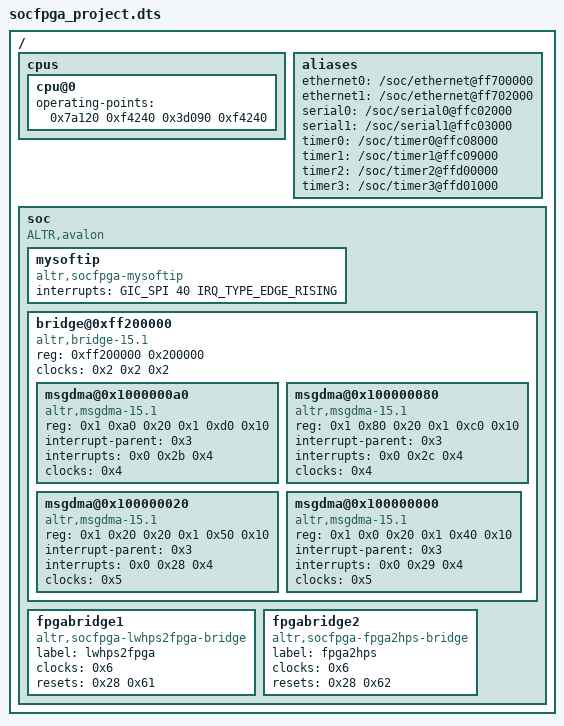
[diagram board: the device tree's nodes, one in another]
#include <dt-bindings/interrupt-controller/irq.h>
#include <dt-bindings/interrupt-controller/arm-gic.h>
#include "socfpga_cyclone5_de0_sockit.dts"

/{


	cpus {		
		cpu@0 {
					operating-points = <0x7a120 0xf4240 0x3d090 0xf4240>;
		};
	};


	aliases {
		ethernet0 = "/soc/ethernet@ff700000";
		ethernet1 = "/soc/ethernet@ff702000";
		serial0 = "/soc/serial0@ffc02000";
		serial1 = "/soc/serial1@ffc03000";
		timer0 = "/soc/timer0@ffc08000";
		timer1 = "/soc/timer1@ffc09000";
		timer2 = "/soc/timer2@ffd00000";
		timer3 = "/soc/timer3@ffd01000";
	};

	soc{

		compatible = "ALTR,avalon", "simple-bus";

		mysoftip{
			compatible="altr,socfpga-mysoftip";
			interrupts=<GIC_SPI 40 IRQ_TYPE_EDGE_RISING>;
		};


		bridge@0xff200000 {
			compatible = "altr,bridge-15.1", "simple-bus";
			reg = <0xff200000 0x200000>;
			clocks = <0x2 0x2 0x2>;
			clock-names = "h2f_lw_axi_clock", "f2h_sdram0_clock", "f2h_sdram1_clock";
			#address-cells = <0x2>;
			#size-cells = <0x1>;
			ranges = <0x1 0xa0 0xff2000a0 0x20 0x1 0x80 0xff200080 0x20 0x1 0xd0 0xff2000d0 0x10 0x1 0xc0 0xff2000c0 0x10 0x1 0x70 0xff200070 0x10 0x1 0x60 0xff200060 0x10 0x1 0x20 0xff200020 0x20 0x1 0x0 0xff200000 0x20 0x1 0x50 0xff200050 0x10 0x1 0x40 0xff200040 0x10>;

			msgdma@0x1000000a0 {
				compatible = "altr,msgdma-15.1", "altr,msgdma-1.0";
				reg = <0x1 0xa0 0x20 0x1 0xd0 0x10>;
				reg-names = "csr", "descriptor_slave";
				interrupt-parent = <0x3>;
				interrupts = <0x0 0x2b 0x4>;
				clocks = <0x4>;
			};

			msgdma@0x100000080 {
				compatible = "altr,msgdma-15.1", "altr,msgdma-1.0";
				reg = <0x1 0x80 0x20 0x1 0xc0 0x10>;
				reg-names = "csr", "descriptor_slave";
				interrupt-parent = <0x3>;
				interrupts = <0x0 0x2c 0x4>;
				clocks = <0x4>;
			};

			msgdma@0x100000020 {
				compatible = "altr,msgdma-15.1", "altr,msgdma-1.0";
				reg = <0x1 0x20 0x20 0x1 0x50 0x10>;
				reg-names = "csr", "descriptor_slave";
				interrupt-parent = <0x3>;
				interrupts = <0x0 0x28 0x4>;
				clocks = <0x5>;
			};

			msgdma@0x100000000 {
				compatible = "altr,msgdma-15.1", "altr,msgdma-1.0";
				reg = <0x1 0x0 0x20 0x1 0x40 0x10>;
				reg-names = "csr", "descriptor_slave";
				interrupt-parent = <0x3>;
				interrupts = <0x0 0x29 0x4>;
				clocks = <0x5>;
			};
		};

		fpgabridge1 {
			compatible = "altr,socfpga-lwhps2fpga-bridge";
			label = "lwhps2fpga";
			reset-names = "lwhps2fpga";
			clocks = <0x6>;
			resets = <0x28 0x61>;
		};

		fpgabridge2 {
			compatible = "altr,socfpga-fpga2hps-bridge";
			label = "fpga2hps";
			reset-names = "fpga2hps";
			clocks = <0x6>;
			resets = <0x28 0x62>;
		};



	};
};
